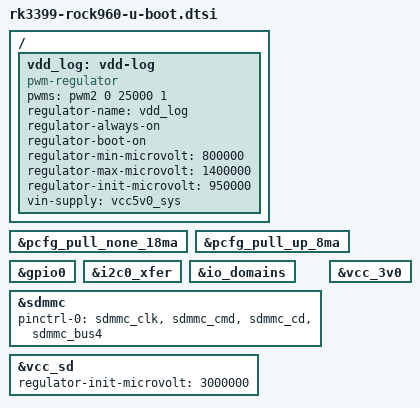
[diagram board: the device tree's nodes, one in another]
// SPDX-License-Identifier: GPL-2.0+
/*
 * Copyright (C) 2019 Jagan Teki <jagan@amarulasolutions.com>
 */

#include "rk3399-u-boot.dtsi"
#include "rk3399-sdram-lpddr3-2GB-1600.dtsi"

/ {
	vdd_log: vdd-log {
		compatible = "pwm-regulator";
		pwms = <&pwm2 0 25000 1>;
		regulator-name = "vdd_log";
		regulator-always-on;
		regulator-boot-on;
		regulator-min-microvolt = <800000>;
		regulator-max-microvolt = <1400000>;
		regulator-init-microvolt = <950000>;
		vin-supply = <&vcc5v0_sys>;
	};
};

&pcfg_pull_none_18ma {
	bootph-pre-ram;
	bootph-some-ram;
};

&pcfg_pull_up_8ma {
	bootph-pre-ram;
	bootph-some-ram;
};

&gpio0 {
	bootph-pre-ram;
};

&i2c0_xfer {
	bootph-pre-ram;
};

&io_domains {
	bootph-pre-ram;
};

&sdmmc {
	pinctrl-0 = <&sdmmc_clk &sdmmc_cmd &sdmmc_cd &sdmmc_bus4>;
};

&vcc_3v0 {
    bootph-pre-ram;
	/delete-property/ regulator-always-on;
};

&vcc_sd {
    bootph-pre-ram;
	/delete-property/ regulator-always-on;
	/delete-property/ regulator-boot-on;
	regulator-init-microvolt = <3000000>;
};
